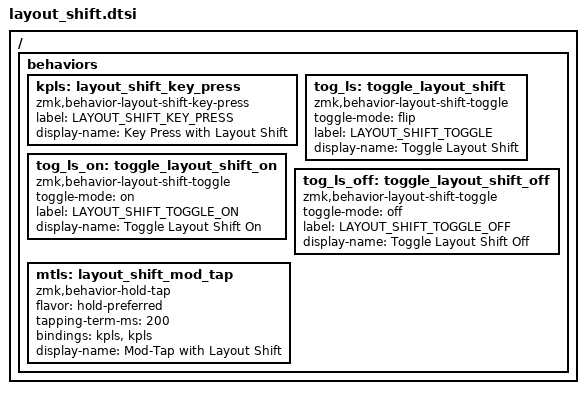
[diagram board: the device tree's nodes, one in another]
/*
 * Copyright (c) 2024 The ZMK Contributors
 *
 * SPDX-License-Identifier: MIT
 */

/* ZMK Layout Shift Module */

#include <dt-bindings/zmk/keys.h>
#include <layouts.dtsi>

/ {
    behaviors {
        // Layout-aware key press behavior alias
        kpls: layout_shift_key_press {
            compatible = "zmk,behavior-layout-shift-key-press";
            #binding-cells = <1>;
            label = "LAYOUT_SHIFT_KEY_PRESS";
            display-name = "Key Press with Layout Shift";
        };

        // Layout shift toggle behaviors
        /omit-if-no-ref/ tog_ls: toggle_layout_shift {
            compatible = "zmk,behavior-layout-shift-toggle";
            #binding-cells = <0>;
            toggle-mode = "flip";
            label = "LAYOUT_SHIFT_TOGGLE";
            display-name = "Toggle Layout Shift";
        };

        /omit-if-no-ref/ tog_ls_on: toggle_layout_shift_on {
            compatible = "zmk,behavior-layout-shift-toggle";
            #binding-cells = <0>;
            toggle-mode = "on";
            label = "LAYOUT_SHIFT_TOGGLE_ON";
            display-name = "Toggle Layout Shift On";
        };

        /omit-if-no-ref/ tog_ls_off: toggle_layout_shift_off {
            compatible = "zmk,behavior-layout-shift-toggle";
            #binding-cells = <0>;
            toggle-mode = "off";
            label = "LAYOUT_SHIFT_TOGGLE_OFF";
            display-name = "Toggle Layout Shift Off";
        };

        // Layout-aware mod-tap behavior alias
        mtls: layout_shift_mod_tap {
            compatible = "zmk,behavior-hold-tap";
            #binding-cells = <2>;
            flavor = "hold-preferred";
            tapping-term-ms = <200>;
            bindings = <&kpls>, <&kpls>;
            display-name = "Mod-Tap with Layout Shift";
        };


    };
};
